# prcm_aon_secure register map
Vendor: Texas Instruments
Registers are 32-bit, access per field, reset 0x0 unless marked. A register's access mark holds for its fields unless they carry their own. Offsets are as the file gives them; [hi:lo] are bit positions; {n}, {i} and the like mark numbered series; <NAME> marks a mode.

## prcm_aon_secure (part 2 of 2)
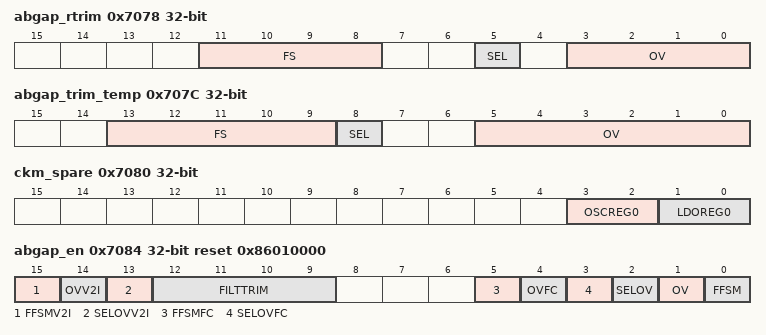
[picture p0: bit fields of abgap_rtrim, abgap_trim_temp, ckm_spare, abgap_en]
0x7078 abgap_rtrim — Analog band gap rtrim
  [11:8] FS ro — fuse value for abgap rtrim
  [5] SEL rw — 1: select override option over the use value : 0: fuse value
  [3:0] OV rw — override value for abgap rtrim
0x707C abgap_trim_temp — ABGAP TRIM TEMP override option over the fuse value for abgap trimcurve
  [13:9] FS ro — fuse value for abgap trim temp To adjust output of amp to 1.224V Nom = 0,0,0,0,0,1 or 1,0,0,0,0,1 Strong = 0,1,1,1,0,0 or 1,1,1,1,0,0 Weak = 0,0,0,1,1,0 or 1,0,0,1,1,0
  [8] SEL rw — 1: select the override option : 0: fuse value
  [5:0] OV rw — override value for abgap trimcurve
0x7080 ckm_spare — CKM SPARE HW connected to abgap
  [3:2] OSCREG0 rw — OSC REGISTER 0
  [1:0] LDOREG0 rw — LDO REGISTER 0
0x7084 abgap_en reset 0x86010000 (reset mask 0xFFFF0000) — ABGAP ENABLE general abgap config
  [15] FFSMV2I ro — FAST FSM V2I FSM status - analog band gap V2I enable
  [14] OVV2I rw — OVERRIDE V2I Enable BG's internal V2I which supplies LDOs "L" = Disable V2I, "H" = Enable V2I
  [13] SELOVV2I rw — SELECT OVERRIDE V2I
  [12:9] FILTTRIM rw — FILT TRIM HW connected to abgap filt trim each bit according to the description below- Control bit for 150k "H" = Bypass resistor , "L" = Enable resistor
  [5] FFSMFC ro — FAST FSM FAST CHARGE FSM status - analog band gap FC enable
  [4] OVFC rw — OVERRIDE FAST CHARGE override value for the abgap fast charge Enable Fast Charge "H" = Enable Fast charging, "L" = Disable
  [3] SELOVFC rw — SELECT OVERRIDE FAST CHARGE 1: select override value for abgap fast charge : 0: use HW FSM for abgap fast charge enable
  [2] SELOV rw — 1: select override value for abgap enable : 0: use HW FSM for abgap enable : : the override value should be written first and then the sel_ov_*; after writing the sel_ov_* the value of the override cannot be changed.
  [1] OV rw — override value for abgap en
  [0] FFSM ro — FAST FSM final abgap enable signal to abgap
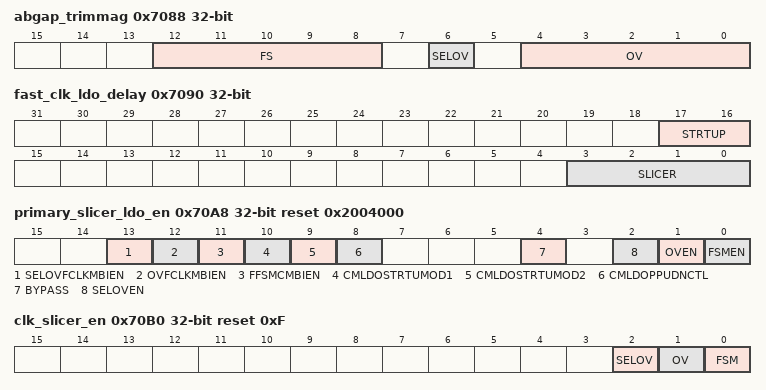
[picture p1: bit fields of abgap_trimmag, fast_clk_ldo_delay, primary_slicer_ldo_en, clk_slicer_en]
0x7088 abgap_trimmag — ABGAP TRIM MAG analog bandgap trimming register
  [12:8] FS ro — fuse value for abgap trimming To adjust output of BG to 800mV Nom = 0,0,0,0,0 Strong = 0,0,0,0,1 Weak = 0,0,0,0,0
  [6] SELOV rw — SELECT OVERRIDE 1: select override value over the fuse value : 0: use fuse value
  [4:0] OV rw — override value for abgap trimming To adjust output of BG to 800mV Nom = 0,0,0,0,0 Strong = 0,0,0,0,1 Weak = 0,0,0,0,0
0x708C fast_clk_req_abgap_delay — FAST CLK REQUEST ABGAP DELAY host clock settling time in FSM
  [10:3] VAL rw — time (sclk) from primary CLK req until FSM enable abgap resolution 250us (need to add 1 to value in register) 0 - 1 slow CLK cycle delay 1 - 2 * 8 sclk cycle delays 2 - 3 * 8 sclk cycle delay ... write [10:3] as 250us resolution read [10:0] - reflect the multiplication by 8 already
0x7090 fast_clk_ldo_delay reset not defined — FAST CLK LDO DELAY primary clock FSM timers
  [17:16] STRTUP rw — delay time for LDO STARTUP to slicer enable or osc_sli_bias_startup (need to add 1 to value in register) 0 - 1 cycle delay 1 - 2 cycle delay
  [3:0] SLICER rw — settling time (sclk) for slicer LDO en. (at least 3-5 slow clks minimum): time from FSM enables the slicer LDO to the time it enables the ldo startup (need to add 1 to value in register) 0 - 1 cycle delay 1 - 2 cycle delay
0x7094 fast_clk_abgap_set_delay reset 0x77 — FAST CLK ABGAP SET DELAY analog bandgap settling time
  [3:0] VAL rw — time (sclk) for analog bandgap settling by fast clock FSM. time from enabling the ABGAP to the time enabling the fast slicer LDO enable (need to add 1 to value in register) 0 - skip the ABGAP fast charge altogether and ABGAP will be enabled simultaneously with slicer LDO configurable time (CLK_REQ_ABGAP_DELAY) after the clock request from ELP is issued 1 - 2 cycle delay
0x7098 fast_clk_abgap_fc_delay reset 0x273 — FAST CLK ABGAP FAST CHARGE DELAY analog bandgap fast charge settling time
  [4:0] VAL rw — time (sclk) that the ABGAP will be in fast charge mode after enable (default 6 RTC clocks - confirmed with ABGAP design) (need to add 1 to value in register) 0 - 1 cycle delay 1 - 2 cycle delay
0x709C abgap_dis_delay reset 0x88 — analog bandgap disabling time register Prior initiating SW SOC-AON RST or Debugger SOC-AON RST, this reg should be initialized to it's default value
  [3:0] VAL rw — delay (sclk) from the time fast clock is no valid to the time the ABGAP enable will fall 0 - no delay 1 - 1 sclk cycle delay = 31.25us 2 - 2 sclk cycle delay = 62.5us 3 - 3 sclk cycle delay = 93.75us ...
0x70A0 abgap_testmode — ABGAP TEST MODE HW connected to analog bandgap testmode input
  [1:0] VAL rw — HW connected to analog bandgap testmode input bit[1] - Bring out "BG_PRETRIM_0P8V" through TMUX bit[0] - Bring out "BG_1P2V" through TMUX
0x70A4 primary_sldo_iload — PRIMARY SLICER LDO ILOAD primary slicer LDO configurations
  [1:0] VAL rw — Slicer LDO internal load test condition
0x70A8 primary_slicer_ldo_en reset 0x2004000 (reset mask 0xFFFFC000) — primary slicer LDO configurations
  [13] SELOVFCLKMBIEN rw — SELECT OVERRIDE FAST CLK MODULE BIAS ENABLE 1: select override option for CKM bias en 0:CKM bias en driven by FSM
  [12] OVFCLKMBIEN rw — OVERRIDE FAST CLK MODULE BIAS ENABLE override value for CKM bias en
  [11] FFSMCMBIEN ro — FAST FSM CKM BIAS ENABLE final primary slicer ldo signal going to CLKM
  [10] CMLDOSTRTUMOD1 rw — CLK MODULE LDO STARTUP MODE 1 clock module ldo startup mode 1
  [9] CMLDOSTRTUMOD2 rw — CLOCK MODULE LDO STARTUP MODE 2 clock module ldo startup mode 2
  [8] CMLDOPPUDNCTL rw — CLKM LDO PMOS PULL DOWN EN clock module ldo pmos pull down ctrl '1' - disable '0' - enable
  [4] BYPASS rw — HW connected to slicer ldo bypass input in CLKM
  [2] SELOVEN rw — SELECT OVERRIDE ENABLE 1: select override option for primary slicer ldo : 0:primary slicer driven by FSM
  [1] OVEN rw — OVERRIDE ENABLE override value for primary slicer
  [0] FSMEN ro — FSM ENABLE final primary slicer ldo signal going to CLKM
0x70AC fast_clk_dis_hfxt_delay reset 0x88 — FAST CLK DISABLE HFXT DELAY delay from primary clock valid goes low to buffer and slicer LDO disable Prior initiating SW SOC-AON RST or Debugger SOC-AON RST, this reg should be initialized to it's default value
  [3:0] VAL rw — delay from fast clock valid goes low to slicer ldo, ldo startup, osc enable and slicer enable to disable mode. 0 - no delay 1 - 1 sclk cycle delay = 31.25us 2 - 2 sclk cycle delay = 62.5us 3 - 3 sclk cycle delay = 93.75us ...
0x70B0 clk_slicer_en reset 0xF — CLK SLICER ENABLE enable options for primary slicer
  [2] SELOV rw — 1: select override value for primary slicer en : 0: primary slicer enable from FSM
  [1] OV rw — override value for primary slicer enable signal
  [0] FSM ro — final primary slicer enable signal to CLKM
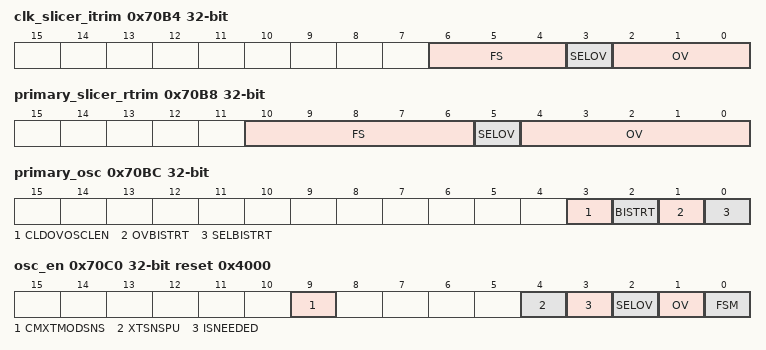
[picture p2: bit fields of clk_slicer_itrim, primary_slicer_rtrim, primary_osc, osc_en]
0x70B4 clk_slicer_itrim — CLK SLICER ITRIM primary slicer trimming register
  [6:4] FS ro — final primary slicer trimming value to CLKM : max hold mechanism of IPs requests
  [3] SELOV rw — 1: select override value for primary slicer trimming over max hold logic : 0: select max hold logic : : the override value should be written first and then the sel_ov_*; after writing the sel_ov_* the value of the override cannot be changed.
  [2:0] OV rw — primary slicer trimming override value
0x70B8 primary_slicer_rtrim — primary clock rtrim cfg register
  [10:6] FS ro — final fast clock rtrim value to CLKM I/F
  [5] SELOV rw — 1: select override option over the fuse value : 0: select override value until efuse shift done and then fuse value
  [4:0] OV rw — override value for clock module rtrim
0x70BC primary_osc — PRIMARY OSCILLATOR
  [3] CLDOVOSCLEN rw — CKM LDO VOUT SCL EN Control bit for bringing out LDO_Vout/2 to GPADC
  [2] BISTRT ro — BIAS START Override control Start-up bit for the Osc/Slicer Bias
  [1] OVBISTRT rw — OVERRIDE BIAS START Override Start-up bit for the Osc/Slicer Bias
  [0] SELBISTRT rw — SELECT BIAS START Override control Start-up bit for the Osc/Slicer Bias
0x70C0 osc_en reset 0x4000 (reset mask 0xFFFFFC00) — OSC ENABLE XTAL cfg register
  [9] CMXTMODSNS ro — CM XTAL MODE SENSE Read value of CLK_IN_PRIMARY_M (XTAL_M) input
  [4] XTSNSPU rw — XTAL SENSE PULL UP enable for the pull resistor in CLKM that detects XTAL mode
  [3] ISNEEDED ro — fast clock detection FSM indication that XTAL oscillator was detected
  [2] SELOV rw — 1: select override value for osc enable signal : 0: osc enable comes from FSM
  [1] OV rw — override value for osc enable signal
  [0] FSM ro — final osc enable signal to CLKM
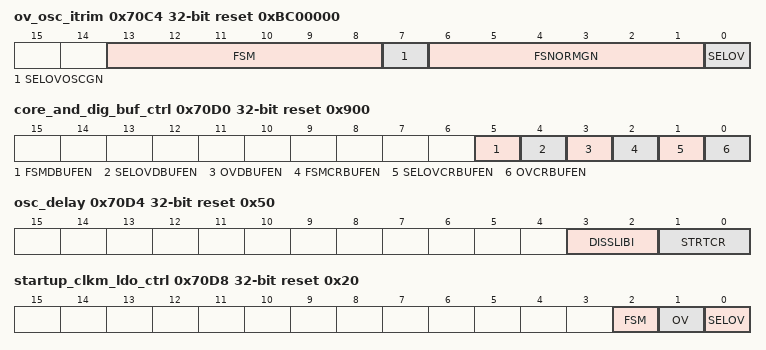
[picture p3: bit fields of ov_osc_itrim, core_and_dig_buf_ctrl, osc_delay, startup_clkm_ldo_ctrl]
0x70C4 ov_osc_itrim reset 0xBC00000 (reset mask 0xFFFFC000) — oscillator itrim cfg register
  [13:8] FSM ro — final XTAL oscillator trimming value to CLKM
  [7] SELOVOSCGN rw — 1: select override for osc gain values, need to use fast_osc_gain_boost (debug only) 0: Logic select between normal and boost values
  [6:1] FSNORMGN ro — FUSE normal gain value
  [0] SELOV rw — 1: select override for osc gain normal values, need to use fast_osc_gain_norm 0: Logic select itrim value
0x70C8 osc_boost_delay reset 0x3C000 (reset mask 0xFFFFFC00) — OSC BOOST DELAY XTAL OSC boost trim cfg
  [9:3] VAL rw — time (sclk) while osc itrim gets boost value before moving to normal value in the clock FSM (default 4ms) resolution 250us (need to add 1 to value in register) 0 - 1 slow CLK cycle delay 1 - 2 * 8 sclk cycle delays 2 - 3 * 8 sclk cycle delay ... write [9:3] as 250us resolution read [9:0] - reflect the multiplication by 8 already
0x70CC osc_normal_delay reset 0xF000 (reset mask 0xFFFFFE00) — OSC NORMAL DELAY XTAL OSC normal trim
  [8:3] VAL rw — time (sclk) while osc itrim gets normal value before moving to next state of opening the buffer in the clock FSM (need to add 1 to value in register) 0 - 1 slow CLK cycle delay 1 - 2 * 8 sclk cycle delays 2 - 3 * 8 sclk cycle delay ... write [8:3] as 250us resolution read [8:0] - reflect the multiplication by 8 already
0x70D0 core_and_dig_buf_ctrl reset 0x900 (reset mask 0xFFFFFFC0) — core and dig buffer control register
  [5] FSMDBUFEN ro — FSM DIGITAL BUFFER ENABLE dig buf enable status
  [4] SELOVDBUFEN rw — SELECT OVERRIDE DIGITAL BUFFER ENABLE select override value or FSM '1' - override '0' - FSM
  [3] OVDBUFEN rw — override digital buffer enable value
  [2] FSMCRBUFEN ro — FAST FSM CORE BUFFER ENABLE core buf enable status
  [1] SELOVCRBUFEN rw — SELECT OVERRIDE CORE BUFFER ENABLE select override value or FSM '1' - override '0' - FSM
  [0] OVCRBUFEN rw — override core buf enable value
0x70D4 osc_delay reset 0x50 (reset mask 0xFFFFFFF0) — OSCILLATOR DELAY XTAL OSC normal trim
  [3:2] DISSLIBI rw — DISABLE SLICER BIAS time (sclk) while fast CLK fsm move from normal gain to disabling the osc_and_sli_bias (need to add 1 to value in register) 0 - 1 cycle delay 1 - 2 cycle delay
  [1:0] STRTCR rw — START CORE time (sclk) while fast CLK FSM slicer is enabled and osc_and_sli_bias to boost mode or to disable osc mode (not in xtal) need to add 1 to value in register) 0 - 1 cycle delay 1 - 2 cycle delay
0x70D8 startup_clkm_ldo_ctrl reset 0x20 (reset mask 0xFFFFFFF8) — startup clock module ldo control
  [2] FSM ro — startup clock module fsm value
  [1] OV rw — override value for startup clock module LDO
  [0] SELOV rw — '1' selects FSM '0' selects override
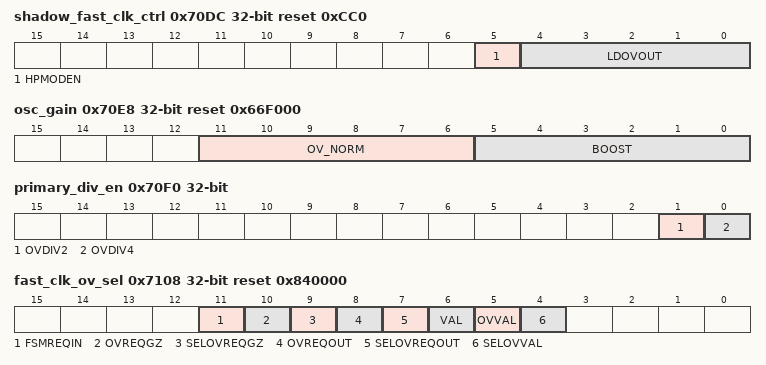
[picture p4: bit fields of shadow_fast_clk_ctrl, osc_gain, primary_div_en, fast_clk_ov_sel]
0x70DC shadow_fast_clk_ctrl reset 0xCC0 (reset mask 0xFFFFFFC0) — SHADOW FAST CLK CONTROL dummy regs control
  [5] HPMODEN rw — HP MODE ENABLE clock module HP mode enable value to push towards dummy once FSM is SLI_LDO_EN
  [4:0] LDOVOUT rw — LDO VOUT clock ldo vout value to push towards dummy once FSM is SLI_LDO_EN
0x70E0 slicer_bias_bypass_ctrl — slicer bias bypass control reg
  [2:0] VAL rw — '1' - slicer bias bypass
0x70E4 ext_clk_req_delay reset 0x84000 (reset mask 0xFFFFF800) — EXTERNAL CLOCK REQUEST DELAY XTAL OSC normal trim
  [10:3] VAL rw — time (sclk) while fast CLK FSM move from ext_CLK_req_wait state to to buffer enable or ip buffer enable resolution 250us (need to add 1 to value in register) 0 - 1 slow CLK cycle delay 1 - 2 * 8 sclk cycle delays 2 - 3 * 8 sclk cycle delay ... write [10:3] as 250us resolution read [10:0] - reflect the multiplication by 8 already
0x70E8 osc_gain reset 0x66F000 (reset mask 0xFFFFF000) — OSC GAIN XTAL oscillator gain control cfg register
  [11:6] OV_NORM rw — gain for normal mode - when enabling
  [5:0] BOOST rw — gain for boost mode - when enabling
0x70EC primary_en_tmux — Primary EN TMUX CFG
  [2:0] VAL rw — HW connected to CLKM - enables the primary slicer ldo output to test mux
0x70F0 primary_div_en — PRIMARY ENABLE primary top digital clock division
  [1] OVDIV2 rw — override divide by 2
  [0] OVDIV4 rw — override divide by 4
0x70F4 push_pull_en — PUSH PULL ENABLE cfg option for the clock to the host
  [0] VAL rw — '1' - enables push pull
0x70F8 fast_clk_dis_clk_out_delay reset 0x88 — FAST CLOCK DISABLE CLK OUT DELAY cfg to hold the clock request out high while FSM is turning off Prior initiating SW SOC-AON RST or Debugger SOC-AON RST, this reg should be initialized to it's default value
  [3:0] VAL rw — time (sclk) from FSM exit EXTEND state (enter CLK_STOP state) to primary clock request out goes low 0 - no delay 1 - 1 sclk cycle delay = 31.25us 2 - 2 sclk cycle delay = 62.5us 3 - 3 sclk cycle delay = 93.75us ...
0x70FC fast_clk_valid_extend_delay — FAST CLK VALID EXTEND DELAY timers for stopping the primary clock
  [2:0] VAL rw — time (sclk) from primary clock valid goes down to the point when the clock actually stops (need to add 1 to value in register) 0 - 1 cycle delay 1 - 2 cycle delay
0x7100 primary_exit_slp_delay — PRIMARY EXIT SLEEP DELAY
  [2:0] VAL rw — time (sclk) from IPs stop asking for primary clock to the time the valid will go down (need to add 1 to value in register) 0 - 1 cycle delay 1 - 2 cycle delay
0x7108 fast_clk_ov_sel reset 0x840000 (reset mask 0xFFFFF000) — fast CLK control over selectors and overrides
  [11] FSMREQIN ro — primary clock request indication to FSM
  [10] OVREQGZ rw — fast CLK request gz override Override CLK req to pad (GZ)
  [9] SELOVREQGZ rw — fast CLK request gz select Override CLK req to pad (GZ)
  [8] OVREQOUT rw — fast CLK request out override Override CLK req to pad (A)
  [7] SELOVREQOUT rw — fast CLK request out select Override CLK req to pad (A)
  [6] VAL ro — primary clock valid indication status
  [5] OVVAL rw — OVERRIDE VALUE fast CLK valid override Override fref valid
  [4] SELOVVAL rw — SELECT OVERRIDE VALUE fast CLK valid select Override fref valid
0x710C fast_clk_duration_delay reset 0x5 — Primary TMUX CFG
  [1:0] STOP rw — time (sclk) from end of CLK_STOP state elapse to CLK_OFF '0' - bypass '1' - 1 + 8 sclks delay ~250us '2' - 1 + 16 sclks delay ~500us '3' - 1 + 32 sclks delay ~1ms
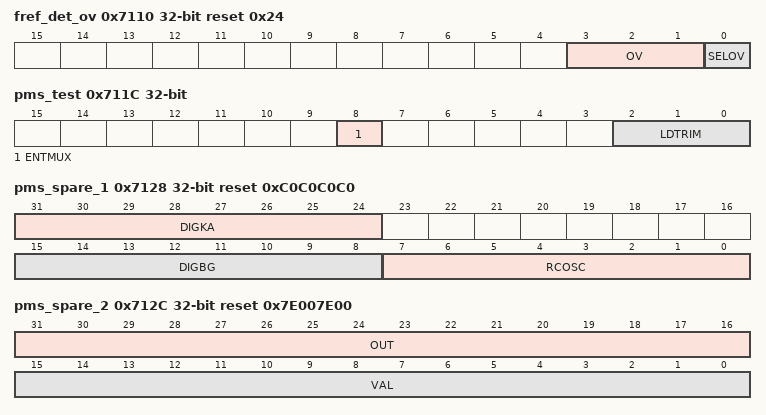
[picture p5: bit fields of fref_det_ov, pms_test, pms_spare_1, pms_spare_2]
0x7110 fref_det_ov reset 0x24 (reset mask 0xFFFFFFFE) — FREF DETECTION
  [3:1] OV rw — 0: 10MHz 1: 26MHz 2: 40MHz 3: 52MHz
  [0] SELOV rw — '1' - fref detection value to pll sharing will be override '0' - fast CLK fsm (fref) value is selected
0x7114 fast_clk_fsm_sop_ov — this is a SOP OV reg, which is a shadow register. user need to lower ELP CLK req and rise it again in order for the OV reg to take action.
  [0] SEL rw — '1' - use sop override for fast CLK fsm '0' - use sop status
0x7118 pms_rnwell_calib — HW connected to PMCIO - To enable the Rnwell calibration
  [0] EN rw — To enable the Rnwell calibration
0x711C pms_test — PMCIO test configurations
  [8] ENTMUX rw — HW connected to PMCIO - Enable signal for test mux
  [2:0] LDTRIM rw — HW connected to PMCIO - Trim bist for LDO test loads
0x7120 pms_tmux_ctrl rw — Test mux control signals. To be decoded one hot
  [31:0] VAL — value switch number Signal 0x00000000 None hi-Z 0x00000001 0 irefn_bg_2u_1p8v[1] 0x00000002 1 irefn_slp_1u_1p8v[1] 0x00000004 2 vref_0p9v_post_filt_pmu 0x00000008 3 vbg_1p22v_lowv 0x00000010 4 sramka_testout_1p8v 0x00000020 5 vdd_sram_sense_lowv 0x00000040 6 no-connect 0x00000080 7 gen_rf_1p8v 0x00000100 8 digka_testout_1p8v 0x00000200 9 mask_digldo_en_1p2_subreg_lowv 0x00000400 10 vcntrl_socpll_1p8v 0x00000800 11 ibias_socpll_1p8v 0x00001000 12 test_comp_out_bod_rvm 0x00002000 13 test_rlad_bod_rvm 0x00004000 14 crude_ref_lowv 0x00008000 15 all_supplies_ok_1p8v 0x00010000 16 vt_det_1p8v 0x00020000 17 test_out_dig_sup_mux 0x00040000 18 iref_bg_test_10u_1p8v 0x00080000 19 irefp_v2i_test_10u_1p8v 0x00100000 20 vdd_core_lowv 0x00200000 21 no-connect 0x00400000 22 no-connect 0x00800000 23 no-connect 0x01000000 24 no-connect 0x02000000 25 no-connect 0x04000000 26 gpadc_input_buf_lowv 0x08000000 27 irefp_v2i_test_10u_1p8v_mirrored 0x10000000 28 don't enable 0x20000000 29 no-connect 0x40000000 30 no-connect 0x80000000 31 no-connect
0x7124 pms_spare_0 — PMS SPARE REG 0 HW connected to PMCIO
  [15:0] DIGLDO rw — DIGITAL LDO
0x7128 pms_spare_1 reset 0xC0C0C0C0 — PMS SPARE REG 1 HW connected to PMCIO
  [31:24] DIGKA rw — DIGITAL KEEP ALIVE SPARE REGISTER
  [15:8] DIGBG rw — DIGITAL BAND GAP SPARE REGISTER
  [7:0] RCOSC rw — RCOSC SPARE REG
0x712C pms_spare_2 reset 0x7E007E00 — PMS SPARE REG 2 HW connected to PMCIO
  [31:16] OUT ro — VALUE
  [15:0] VAL rw — VALUE [9:5] - dig ldo test mux control [4:0] - sram test mux control
0x7130 pms_ctrl_and_status ro reset 0x3636 — PMS CONTROL STATUS PMS FSM cfg register
  [7:0] STA — PMS STATE Following FSM controls PMU for mode transition from ACTIVE to HIBERNATE/LPDS and vice-versa Power Mode PMU sequence: (Go to sleep sequence example. Wakeup is reversed order) bit[0] - LDOs_KA (enable KA LDO's... - wait 1c) bit[1] - LDO_SRAM (disable SRAM LDO... - wait 1c) bit[2] - LDO_DIG (disable DIG LDO... - wait 1c) bit[3] - RVM_LPM (enable RVM Low Power Mode... - wait 1c) bit[4] - BG_CAP_SW (disable BandGap Cap switch... - wait 1c) bit[5] - BG (disable BandGap - wait 1c) localparam [7:0] PM_ACT = 8'b00_110110 , // ACTIVE - Steady State nr. 1 PM_GTS_LDO_KA_EN = 8'b00_110111 , PM_GTS_LDO_SRAM_DIS = 8'b00_110101 , PM_GTS_LDO_DIG_DIS = 8'b00_110001 , PM_GTS_RVM_LPM_EN = 8'b00_111001 , PM_GTS_BG_CAP_SW_DIS = 8'b00_101001 , PM_GTS_BG_DIS = 8'b00_001001 , PM_SLP = 8'b01_001001 , // SLEEP - Steady State nr. 2 (up to 20ms) PM_SLP_TO_RFRSH = 8'b01_101001 , PM_RFRSH = 8'b01_111001 , // Refresh - Steady State nr. 3 (up to 100us) PM_RFRSH_TO_SLP = 8'b10_101001 , PM_WKU_BG_EN = 8'b11_101001 , PM_WKU_BG_CAP_SW_EN = 8'b11_111001 , PM_WKU_RVM_LPM_DIS = 8'b11_110001 , PM_WKU_LDO_DIG_EN = 8'b11_110101 , PM_WKU_LDO_SRAM_EN = 8'b11_110111 , PM_WKU_LDO_KA_DIS = 8'b11_110110 ;
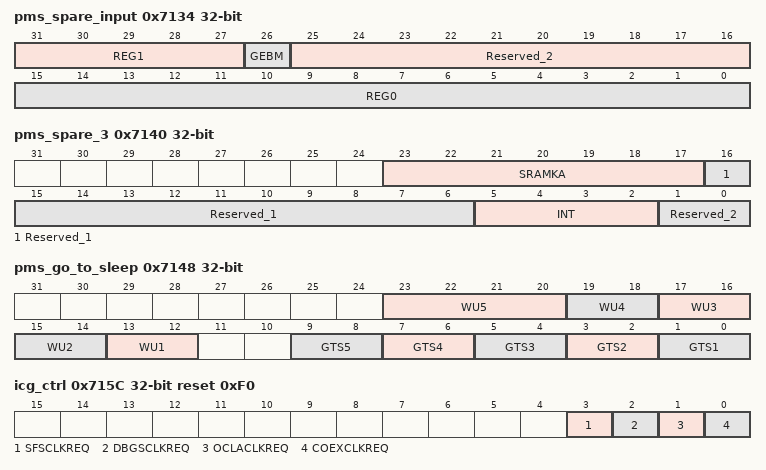
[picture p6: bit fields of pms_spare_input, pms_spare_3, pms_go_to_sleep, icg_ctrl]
0x7134 pms_spare_input — PMS SPARE INPUT HW connected to PMCIO - spare input from PMCIO
  [31:27] REG1 rw — SPARE_REG1 bit map [15:11] bit <15>- in PMU: no usage. Should not be used. In PRCM: selects MMR control (S/W) mem_bod_comp_en/mem_rvml_comp_en/mem_rvmh_comp_en over the default control (H/W) for comparators BOD/RVML/RVMH enable respectively
  [26] GEBM rw — SPARE_REG1 bit map [10]: used for VBOXLO test
  [25:16] Reserved_2 ro — SPARE_REG1 bit map [9:0]: [3:0] - pmcio_spare_bits_buf[3:0], set by writing to GPADC REGS MEM_GPADC_PMCIO_SPARE_RX/TX_1/2 [4] - host_elp_wdt_req, set by HOST ELP WDT elapsed [5] - debugss_debug_req, set by debugss reset request [6] - 1'b0 [7] - set by writing to mem_rst_wdt_cause_clr, clears reset cause [8] - set by writing to mem_rst_debugss_cause_clr, clears reset cause [9] - 1'b0
  [15:0] REG0 rw — REGISTER 0 <11> - '1' mask BOD and RVMs for 2 cycles in LPDS entry
0x7138 pms_por_test_ctrl — PMS POR TEST CONTROL Test Mode control for POR POL block
  [7:0] VAL rw — HW connected to PMCIO
0x7140 pms_spare_3 reset not defined — PMS SPARE 3 HW connected to PMCIO
  [23:17] SRAMKA rw — SRAM KEEP ALIVE
  [16:6] Reserved_1 ro — bit [16] is bit[0] of SRAMKA_SPARE port used as - fsm_prcm_ldo_wku_sram_ka_clamp
  [5:2] INT rw — INTERNAL
  [1:0] Reserved_2 ro — bit [0] - por_comp_out_mask_en bit [1] - vtdet_comp_out_mask_en
0x7144 pms_spare_4 reset 0x7E007E00 — PMS SPARE 4 HW connected to PMCIO
  [15:0] PMBIST rw — [5:4] - rfcio test switch [3:2] - adc test switch [1] - vdd main divider enable [0] - i2v divider enable
0x7148 pms_go_to_sleep reset not defined — PMS DELAYS HW connected to PMCIO - spare input from PMCIO
  [23:20] WU5 rw — WAKEUP DELAY 5 delay from PM_WKU_LDO_SRAM_EN to PM_WKU_LDO_KA_DIS for additional details please review following page: https://confluence.itg.ti.com/pages/viewpage.action?spaceKey=WNG&title=Osprey+PRCM+-+PMU Also used as LDO inrush Limit timer: 0- inrush limit to LDO's will be set 1 slow clock cycle (32us) after DIG LDO has been set 1- inrush limit to LDO's will be set 2 slow clock cycles (64us) after DIG LDO has been set (default) 2- inrush limit to LDO's will be set 3 slow clock cycles (96us) after DIG LDO has been set ... 15- inrush limit to LDO's will be set 16 slow clock cycles (16*32us) after DIG LDO has been set Note that SRAM LDO is set 1-4 cycles (1 is default) before DIG LDO is set. Inrush Limit covers both.
  [19:18] WU4 rw — WAKEUP DELAY 4 delay from PM_WKU_LDO_DIG_EN to PM_WKU_LDO_SRAM_EN for additional details please review following page: https://confluence.itg.ti.com/pages/viewpage.action?spaceKey=WNG&title=Osprey+PRCM+-+PMU
  [17:16] WU3 rw — WAKEUP DELAY 3 delay from PM_WKU_RVM_LPM_DIS to PM_WKU_LDO_DIG_EN for additional details please review following page: https://confluence.itg.ti.com/pages/viewpage.action?spaceKey=WNG&title=Osprey+PRCM+-+PMU
  [15:14] WU2 rw — WAKEUP DELAY 2 delay from PM_WKU_BG_CAP_SW_EN to PM_WKU_RVM_LPM_DIS for additional details please review following page: https://confluence.itg.ti.com/pages/viewpage.action?spaceKey=WNG&title=Osprey+PRCM+-+PMU
  [13:12] WU1 rw — WAKEUP DELAY 1 delay from PM_WKU_BG_EN to PM_WKU_BG_CAP_SW_EN for additional details please review following page: https://confluence.itg.ti.com/pages/viewpage.action?spaceKey=WNG&title=Osprey+PRCM+-+PMU
  [9:8] GTS5 rw — GO TO SLEEP DELAY 5 delay from PM_GTS_BG_CAP_SW_DIS to PM_GTS_BG_DIS for additional details please review following page: https://confluence.itg.ti.com/pages/viewpage.action?spaceKey=WNG&title=Osprey+PRCM+-+PMU
  [7:6] GTS4 rw — GO TO SLEEP DELAY 4 delay from PM_GTS_RVM_LPM_EN to PM_GTS_BG_CAP_SW_DIS for additional details please review following page: https://confluence.itg.ti.com/pages/viewpage.action?spaceKey=WNG&title=Osprey+PRCM+-+PMU
  [5:4] GTS3 rw — GO TO SLEEP DELAY 3 delay from PM_GTS_LDO_DIG_DIS to PM_GTS_RVM_LPM_EN for additional details please review following page: https://confluence.itg.ti.com/pages/viewpage.action?spaceKey=WNG&title=Osprey+PRCM+-+PMU
  [3:2] GTS2 rw — GO TO SLEEP DELAY 2 delay from PM_GTS_LDO_SRAM_DIS to PM_GTS_LDO_DIG_DIS for additional details please review following page: https://confluence.itg.ti.com/pages/viewpage.action?spaceKey=WNG&title=Osprey+PRCM+-+PMU
  [1:0] GTS1 rw — GO TO SLEEP DELAY 1 delay from PM_GTS_LDO_KA_EN to PM_GTS_LDO_SRAM_DIS for additional details please review following page: https://confluence.itg.ti.com/pages/viewpage.action?spaceKey=WNG&title=Osprey+PRCM+-+PMU
0x714C bg_dis_bg_en_delay reset 0x2D — DIGITAL BANDGAP DISABLE BANDGAP ENABLE DELAY time (sclk) in DBGAP hibernate mode
  [2:0] SLP rw — SLEEP The sleep duration between refresh intervals - from BG disable (Going to Sleep) to BG enable (waking for refresh). Granularity is 128 clocks (clock period is 31.25us) hence: "000" - N.A "001" - 4ms "010" - 8ms "011" - 12ms "100" - 16ms "101" - 20ms (default) "110" - 24ms "111" - 28ms
0x7150 sw_en_sw_dis_delay reset 0x1B — SW ENABLE SW DISABLE DELAY time (sclk) in DBGAP hibernate mode
  [2:0] SLP rw — SLEEP The Refresh duration - from Switch enable (go in refresh) to Switch disable (go out of refresh). Granularity is 1 clock (clock period is 31.25us) hence: "000" - 31.25us "001" - 62.5us "010" - 93.75us "011" - 125us (default) "100" - 156.25us "101" - 187.5us "110" - 218.75us "111" - 250us
0x7154 bg_en_sw_en_sleep_delay reset 0x5 — BANDGAP ENABLE SW ENABLE SLEEP DELAY time (sclk) in DBGAP hibernate mode
  [1:0] SLP rw — SLEEP The duration from BG enable to SW enable (transition to refresh). Granularity is 1 clock (clock period is 31.25us) hence: "000" - 31.25us "001" - 62.5us (default) "010" - 93.75us "011" - 125us "100" - 156.25us "101" - 187.5us "110" - 218.75us "111" - 250us
0x7158 sw_dis_bg_dis_sleep_delay reset 0x5 — SW DISABLE BANDGAP DISABLE DELAY time (sclk) in DBGAP hibernate mode
  [1:0] SLP rw — SLEEP The duration from SW disable to BG disable (transition from refresh). Granularity is 1 clock (clock period is 31.25us) hence: "000" - 31.25us "001" - 62.5us (default) "010" - 93.75us "011" - 125us "100" - 156.25us "101" - 187.5us "110" - 218.75us "111" - 250us
0x715C icg_ctrl reset 0xF0 (reset mask 0xFFFFFFF0) — ICG CONTROL
  [3] SFSCLKREQ rw — SLOW FUSE CLK REQ '1' - request CLK for prcm fuse farm. default is '1'. S/W will clr to save power
  [2] DBGSCLKREQ rw — '1' - request CLK for debugss
  [1] OCLACLKREQ rw — '1' - request CLK for ocla
  [0] COEXCLKREQ rw — '1' - request CLK for coex
0x7160 halt
  [0] DBGSEL rw — select debug halt source: 0 - M33 Halt 1 - M3 Halt
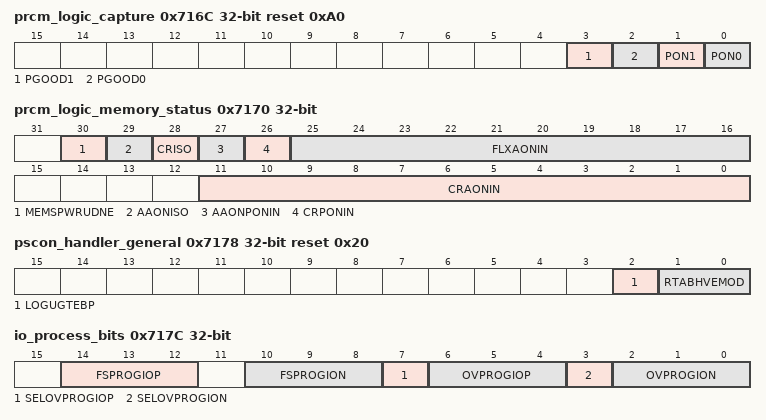
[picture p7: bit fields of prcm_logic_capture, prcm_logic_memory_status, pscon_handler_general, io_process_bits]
0x716C prcm_logic_capture ro reset 0xA0 (reset mask 0xFFFFFFF0) — LOGIC CAPTURE
  [3] PGOOD1 — read clear CORE PGOOD indication set
  [2] PGOOD0 — read clear CORE PGOOD indication fall
  [1] PON1 — read clear CORE PON indication set
  [0] PON0 — read clear CORE PON indication fall
0x7170 prcm_logic_memory_status ro reset not defined — LOGIC MEMORY STATUS
  [30] MEMSPWRUDNE — MEMORIES POWERUP DONE
  [29] AAONISO
  [28] CRISO — CORE ISO
  [27] AAONPONIN
  [26] CRPONIN — CORE PONIN
  [25:16] FLXAONIN — FLEX AONIN
  [11:0] CRAONIN — CORE AONIN
0x7174 prcm_hol_state ro — HOLISTIC FSM
  [4:0] STA — STATE HOL_IDLE = 5'b00000 HOL_HW_BOOT1 = 5'b00001 HOL_HW_BOOT2 = 5'b00010 HOL_HW_BOOT3 = 5'b00011 HOL_ACTIVE2 = 5'b00100 HOL_ACTIVE3 = 5'b00101 HOL_ACTIVE4 = 5'b00110 HOL_TRN_TRUE_SLEEP1 = 5'b00111 HOL_TRN_TRUE_SLEEP2 = 5'b01000 HOL_TRN_TRUE_SLEEP3 = 5'b01001 HOL_TRUE_SLEEP = 5'b01010 HOL_PRCM_VLD_ACTIVE3 = 5'b01011 HOL_AAON_ACTIVE3 = 5'b01100 HOL_CORE_SLP_ACTIVE3 = 5'b01101 HOL_CORE_ACT_ACTIVE3 = 5'b01110 HOL_PRCM_VLD_ACTIVE4 = 5'b01111 HOL_AAON_ACTIVE4 = 5'b10000 HOL_HOST_SLP_ACTIVE4 = 5'b10001 HOL_HOST_ACT_ACTIVE4 = 5'b10010
0x7178 pscon_handler_general reset 0x20 (reset mask 0xFFFFFFF8)
  [2] LOGUGTEBP rw — LOGIC UNGATE BYPASS '1' - bypass the logic UNGATE request option '0' - logic will generate ungate request
  [1:0] RTABHVEMOD rw — NU at MDB Determine the RTA behavior in sleep/true sleep: [0] - SLEEP MODE [1] - TRUE SLEEP MODE 0 - OFF/OFF : in case issues with RTA toggling in sleep 1 - OFF/ON : in case no ret in true sleep + in case issues with RTA toggling in sleep 2 - ON/OFF : POR 3 - ON/ON : In case use ret in true sleep
0x717C io_process_bits
  [14:12] FSPROGIOP ro — FUSE PROGIO P OVERRIDE PROGIO N Bit 2 is inverted between MMR and PAD -> so to configure the values 1,3,6 according to the corner, we need to set the registers to 5,7,2: MAX: MMR --> p=n=2 ; PAD --> p=n=6 NOM: MMR --> p=n=7 ; PAD --> p=n=3 MIN: MMR --> p=n=5 ; PAD --> p=n=1
  [10:8] FSPROGION ro — FUSE PROGIO N OVERRIDE PROGIO N Bit 2 is inverted between MMR and PAD -> so to configure the values 1,3,6 according to the corner, we need to set the registers to 5,7,2: MAX: MMR --> p=n=2 ; PAD --> p=n=6 NOM: MMR --> p=n=7 ; PAD --> p=n=3 MIN: MMR --> p=n=5 ; PAD --> p=n=1
  [7] SELOVPROGIOP rw — SELECT OVERRIDE PROGIO P process bit to io set
  [6:4] OVPROGIOP rw — OVERRIDE PROGIO P OVERRIDE PROGIO N Bit 2 is inverted between MMR and PAD -> so to configure the values 1,3,6 according to the corner, we need to set the registers to 5,7,2: MAX: MMR --> p=n=2 ; PAD --> p=n=6 NOM: MMR --> p=n=7 ; PAD --> p=n=3 MIN: MMR --> p=n=5 ; PAD --> p=n=1
  [3] SELOVPROGION rw — SELECT OVERRIDE PROIO N process bit to io set
  [2:0] OVPROGION rw — OVERRIDE PROGIO N Bit 2 is inverted between MMR and PAD -> so to configure the values 1,3,6 according to the corner, we need to set the registers to 5,7,2: MAX: MMR --> p=n=2 ; PAD --> p=n=6 NOM: MMR --> p=n=7 ; PAD --> p=n=3 MIN: MMR --> p=n=5 ; PAD --> p=n=1
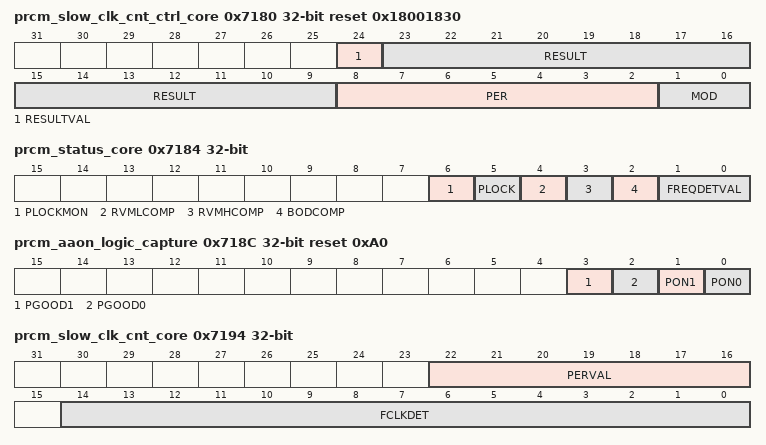
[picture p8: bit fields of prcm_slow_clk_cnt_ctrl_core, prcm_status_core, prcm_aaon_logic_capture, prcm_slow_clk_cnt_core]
0x7180 prcm_slow_clk_cnt_ctrl_core ro reset 0x18001830 (reset mask 0xFEFFFFFC) — SLOW CLOCK COUNT CONTROL CORE
  [24] RESULTVAL — RESULT VALID Determine whether the measurement is in progress or done: 0x0 - In progress (Relevant in one shot only) 0x1 - Done (when finish measurement and result ready)
  [23:9] RESULT — Slow Clock counter result
  [8:2] PER — Determine the Slow clock counter period (Slow Clock cycles), 1 - 128. '0' - 1 CLK cycle '1' - 2 CLK cycles '2' - 3 CLK cycles ... '127' - 128 CLK cycles
  [1:0] MOD — MODE Determine the Slow clock counter mode- 0x3 - Reserved 0x2 - Periodic 0x1 - One Shot 0x0 - Disable
0x7184 prcm_status_core ro — STATUS CORE
  [6] PLOCKMON — PLL SHARING LOCK MONITOR
  [5] PLOCK — '1' - pll sharing pll lock
  [4] RVMLCOMP — '1' - GOOD
  [3] RVMHCOMP — '1' - GOOD
  [2] BODCOMP — '1' - GOOD
  [1:0] FREQDETVAL — fast clock frequency detection value : 0: 10MHz 1: 26MHz 2: 40MHz 3: 52MHz
0x718C prcm_aaon_logic_capture ro reset 0xA0 (reset mask 0xFFFFFFF0) — AAON LOGIC CAPTURE
  [3] PGOOD1 — read clear AAON PGOOD indication set
  [2] PGOOD0 — read clear AAON PGOOD indication fall
  [1] PON1 — read clear AAON PON indication set
  [0] PON0 — read clear AAON PON indication fall
0x7190 host_wdt — HOST WATCH DOG TIMER
  [0] FSENOV rw — FUSE ENABLE OVERRIDE '1'- override fuse bit value (regular operation) '0'- use fuse bit value.
0x7194 prcm_slow_clk_cnt_core ro — SLOW CLK COUNT CORE
  [22:16] PERVAL — PERIOD VALUE slow CLK current value. bounds are 0 to slow_clk_counter_period
  [14:0] FCLKDET — FAST CLK DETECTION COUNTER Counter results for 4 slow clock freq lower upper (MHz) (dec) (dec) 10 1190 1503 26 3094 3908 40 4760 6012 52 6188 7815
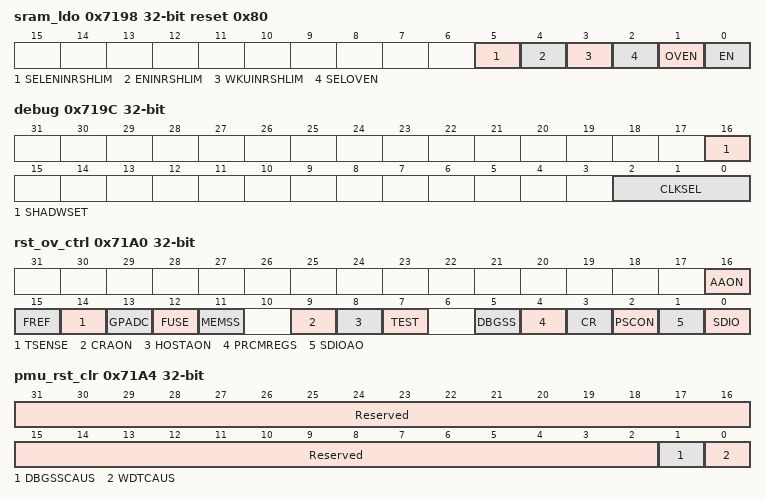
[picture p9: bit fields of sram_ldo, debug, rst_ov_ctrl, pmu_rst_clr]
0x7198 sram_ldo reset 0x80 (reset mask 0xFFFFFFC0) — SRAM LDO gen cfg register
  [5] SELENINRSHLIM rw — SELECT ENABLE INRUSH LIMIT Select for S/W Enabling the Inrush Current Limit Mask
  [4] ENINRSHLIM rw — Enable Inrush Current Limit Mask
  [3] WKUINRSHLIM ro — WAKEUP INRUSH LIMIT status of final SRAM LDO enable
  [2] SELOVEN rw — SELECT OVERRIDE ENABLE 1: select override value for SRAM LDO enable : 0: SRAM LDO enable from FSM
  [1] OVEN rw — OVERRIDE ENABLE override value for SRAM LDO
  [0] EN ro — ENABLE status of final SRAM LDO enable
0x719C debug
  [16] SHADWSET rw — SHADOW SET '1' - override condition to load shadow values at FREF and PLLSH
  [2:0] CLKSEL rw — CLOCK SELECT Debug and Fast CLK detection selector 'x00' - prcm_fast_clock. 'x01' - ospr_hsm_tst_fro_clk_out 'x10' - clk_gpadc_clk 'x11' - fref_2m_socpll_1p8v '100' - rf_pll_divided_clk
0x71A0 rst_ov_ctrl — reset override control register, active low polarity: '0' - override reset (force reset line to 0, reset asserted, active low) '1' - don't override reset
  [16] AAON wo — AAON write clear '1' - request CLK for sdio AAON
  [15] FREF wo — FREF write clear '1' - request CLK for FREF
  [14] TSENSE wo — NOT USED write clear '1' - no reset
  [13] GPADC wo — GPADC write clear '1' - request CLK for sdio GPADC
  [12] FUSE wo — FUSE FARM write clear '1' - request CLK for sdio FUSEFARM
  [11] MEMSS wo — MEMORY SUB SYSTEM write clear
  [9] CRAON wo — CORE AON write clear '1' - request CLK for sdio CORE AON
  [8] HOSTAON wo — HOSTAON write clear '1' - request CLK for sdio HOST AON
  [7] TEST wo — NOT USED write clear
  [5] DBGSS wo — DEBUGSS write clear '1' - request CLK for sdio DEBUGSS
  [4] PRCMREGS wo — NOT USED write clear
  [3] CR wo — CORE write clear '1' - request CLK for sdio CORE
  [2] PSCON wo — '1' - request CLK for sdio PSCON write clear
  [1] SDIOAO wo — NOT USED write clear '1' - request CLK for sdio ao
  [0] SDIO wo — NOT USED write clear '1' - request CLK for sdio sw
0x71A4 pmu_rst_clr — PMU RESET CLEAR Level registers- need to set high and low to clear WDT or DEBUGSS indications. Set '1' to those fields will automated a pulse to pmu. clear this field to '0' after use.
  [31:2] Reserved ro — SPARE_REG1 bit map [9:0]: [3:0] - pmcio_spare_bits_buf[3:0], set by writing to GPADC REGS MEM_GPADC_PMCIO_SPARE_RX/TX_1/2 [4] - host_elp_wdt_req, set by HOST ELP WDT elapsed [5] - debugss_debug_req, set by debugss reset request [6] - 1'b0 [7] - set by writing to mem_rst_wdt_cause_clr, clears reset cause [8] - set by writing to mem_rst_debugss_cause_clr, clears reset cause [9] - 1'b0
  [1] DBGSSCAUS rw — PRCM SPARE REG 1 [8] - mem_rst_debugss_cause_clr '1' - clear debugss reset cause
  [0] WDTCAUS rw — PRCM SPARE REG 1 [7] - mem_rst_wdt_cause_clr '1' - clear wdt reset cause
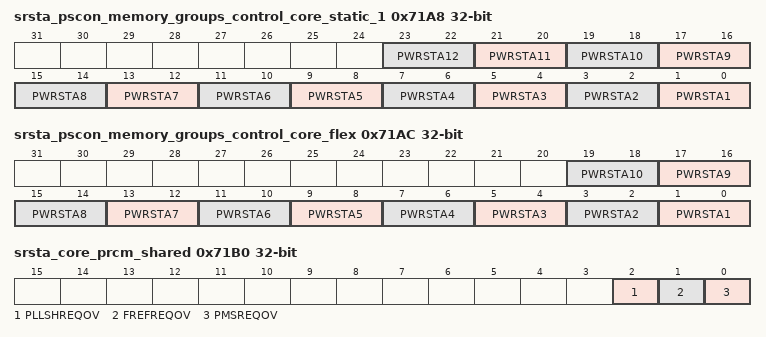
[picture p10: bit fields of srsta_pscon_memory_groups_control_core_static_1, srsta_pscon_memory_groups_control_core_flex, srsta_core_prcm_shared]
0x71A8 srsta_pscon_memory_groups_control_core_static_1 reset not defined — MEMORY GROUP CONTROL CORE STATIC 1 Bank power State When owner IP Active/Sleep (power domain is ON/OFF) 0 - OFF/OFF 1 - Reserved 2 - ON/OFF 3 - ON/RET
  [2n-1:2n-2] PWRSTA{n} rw (n=1..12) — POWER STATE {n} Group {n+10}
0x71AC srsta_pscon_memory_groups_control_core_flex reset not defined — MEMORY GROUP CONTROL CORE FLEX Applicable only if MODE selected flex as CORE memory. Bank power State When owner IP Active/Sleep (power domain is ON/OFF) 0 - OFF/OFF 1 - Reserved 2 - ON/OFF 3 - ON/RET
  [2n-1:2n-2] PWRSTA{n} rw (n=1..10) — POWER STATE {n} Group {n}
0x71B0 srsta_core_prcm_shared — CORE SHARED override values for PRCM SHARED Modules
  [2] PLLSHREQOV rw — PLL SHAREING REQUEST OVERRIDE '1' - keeps awake at sleep state '0' - regular operation note: in order to set this field as '1', FREF OV and PMS OV must be set as well.
  [1] FREFREQOV rw — FREF REQUEST OVERRIDE '1' - keeps awake at sleep state '0' - regular operation note: in order to set this field as '1', PMS OV must be set as well.
  [0] PMSREQOV rw — PMS REQUEST OVERRIDE '1' - keeps awake at sleep state '0' - regular operation
